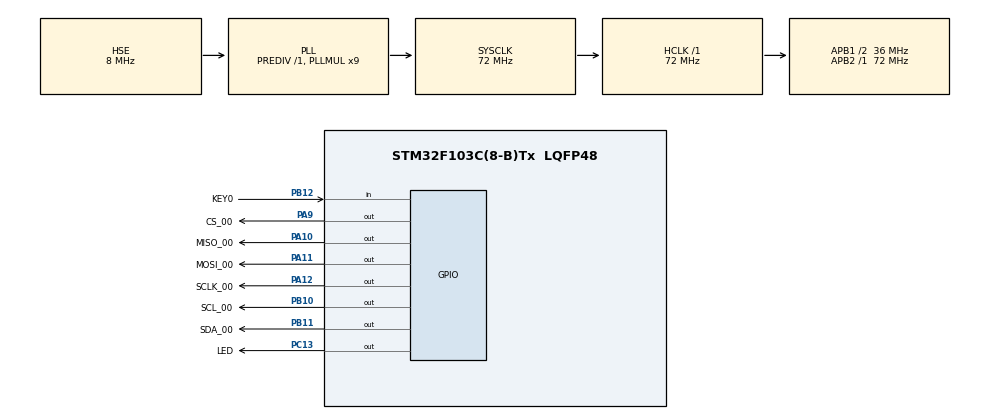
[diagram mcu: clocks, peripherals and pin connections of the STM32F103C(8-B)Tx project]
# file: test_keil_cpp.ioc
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IWDG.Prescaler=IWDG_PRESCALER_64
IWDG.Reload=1000
Mcu.Family=STM32F1
Mcu.Name=STM32F103C(8-B)Tx
Mcu.Package=LQFP48
NVIC.PriorityGroup=NVIC_PRIORITYGROUP_4
PA10.GPIO_Label=MISO_00
PA10.Signal=GPIO_Output
PA11.GPIO_Label=MOSI_00
PA11.Signal=GPIO_Output
PA12.GPIO_Label=SCLK_00
PA12.Signal=GPIO_Output
PA13.Mode=Serial_Wire
PA13.Signal=SYS_JTMS-SWDIO
PA14.Mode=Serial_Wire
PA14.Signal=SYS_JTCK-SWCLK
PA9.GPIO_Label=CS_00
PA9.Signal=GPIO_Output
PB10.GPIO_Label=SCL_00
PB10.Signal=GPIO_Output
PB11.GPIO_Label=SDA_00
PB11.Signal=GPIO_Output
PB12.GPIO_Label=KEY0
PB12.GPIO_PuPd=GPIO_NOPULL
PB12.Signal=GPIO_Input
PC13-TAMPER-RTC.GPIO_Label=LED
PC13-TAMPER-RTC.GPIO_PuPd=GPIO_PULLUP
PC13-TAMPER-RTC.GPIO_Speed=GPIO_SPEED_FREQ_HIGH
PC13-TAMPER-RTC.PinState=GPIO_PIN_SET
PC13-TAMPER-RTC.Signal=GPIO_Output
PC14-OSC32_IN.Mode=LSE-External-Oscillator
PC14-OSC32_IN.Signal=RCC_OSC32_IN
PC15-OSC32_OUT.Mode=LSE-External-Oscillator
PC15-OSC32_OUT.Signal=RCC_OSC32_OUT
PD0-OSC_IN.Mode=HSE-External-Oscillator
PD0-OSC_IN.Signal=RCC_OSC_IN
PD1-OSC_OUT.Mode=HSE-External-Oscillator
PD1-OSC_OUT.Signal=RCC_OSC_OUT
ProjectManager.HeapSize=0x200
ProjectManager.StackSize=0x400
ProjectManager.TargetToolchain=MDK-ARM V5
RCC.AHBFreq_Value=72000000
RCC.APB1CLKDivider=RCC_HCLK_DIV2
RCC.APB1Freq_Value=36000000
RCC.APB1TimFreq_Value=72000000
RCC.APB2Freq_Value=72000000
RCC.APB2TimFreq_Value=72000000
RCC.HCLKFreq_Value=72000000
RCC.PLLMUL=RCC_PLL_MUL9
RCC.PLLSourceVirtual=RCC_PLLSOURCE_HSE
RCC.SYSCLKFreq_VALUE=72000000
RCC.SYSCLKSource=RCC_SYSCLKSOURCE_PLLCLK
RCC.USBFreq_Value=72000000
VP_IWDG_VS_IWDG.Mode=IWDG_Activate
board=custom

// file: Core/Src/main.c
/* USER CODE BEGIN Header */
/**
  ******************************************************************************
  * @file           : main.c
  * @brief          : Main program body
  ******************************************************************************
  * @attention
  *
  * Copyright (c) 2025 STMicroelectronics.
  * All rights reserved.
  *
  * This software is licensed under terms that can be found in the LICENSE file
  * in the root directory of this software component.
  * If no LICENSE file comes with this software, it is provided AS-IS.
  *
  ******************************************************************************
  */
/* USER CODE END Header */
#include "main.h"
#include "iwdg.h"
#include "gpio.h"

/* USER CODE BEGIN Includes */
#include "z_init.h"
#include "z_while.h"
/* USER CODE END Includes */

void SystemClock_Config(void);

int main(void)
{

  /* MCU Configuration--------------------------------------------------------*/

  /* Reset of all peripherals, Initializes the Flash interface and the Systick. */
  HAL_Init();

  /* Configure the system clock */
  SystemClock_Config();

  /* Initialize all configured peripherals */
  MX_GPIO_Init();
  MX_IWDG_Init();
  /* USER CODE BEGIN 2 */
	z_init();
  /* USER CODE END 2 */

  /* Infinite loop */
  while (1)
  {

    /* USER CODE BEGIN 3 */
		z_while();
  }
  /* USER CODE END 3 */
}

void SystemClock_Config(void)
{
  RCC_OscInitTypeDef RCC_OscInitStruct = {0};
  RCC_ClkInitTypeDef RCC_ClkInitStruct = {0};

  /** Initializes the RCC Oscillators according to the specified parameters
  * in the RCC_OscInitTypeDef structure.
  */
  RCC_OscInitStruct.OscillatorType = RCC_OSCILLATORTYPE_LSI|RCC_OSCILLATORTYPE_HSE;
  RCC_OscInitStruct.HSEState = RCC_HSE_ON;
  RCC_OscInitStruct.HSEPredivValue = RCC_HSE_PREDIV_DIV1;
  RCC_OscInitStruct.HSIState = RCC_HSI_ON;
  RCC_OscInitStruct.LSIState = RCC_LSI_ON;
  RCC_OscInitStruct.PLL.PLLState = RCC_PLL_ON;
  RCC_OscInitStruct.PLL.PLLSource = RCC_PLLSOURCE_HSE;
  RCC_OscInitStruct.PLL.PLLMUL = RCC_PLL_MUL9;
  if (HAL_RCC_OscConfig(&RCC_OscInitStruct) != HAL_OK)
  {
    Error_Handler();
  }

  /** Initializes the CPU, AHB and APB buses clocks
  */
  RCC_ClkInitStruct.ClockType = RCC_CLOCKTYPE_HCLK|RCC_CLOCKTYPE_SYSCLK
                              |RCC_CLOCKTYPE_PCLK1|RCC_CLOCKTYPE_PCLK2;
  RCC_ClkInitStruct.SYSCLKSource = RCC_SYSCLKSOURCE_PLLCLK;
  RCC_ClkInitStruct.AHBCLKDivider = RCC_SYSCLK_DIV1;
  RCC_ClkInitStruct.APB1CLKDivider = RCC_HCLK_DIV2;
  RCC_ClkInitStruct.APB2CLKDivider = RCC_HCLK_DIV1;

  if (HAL_RCC_ClockConfig(&RCC_ClkInitStruct, FLASH_LATENCY_2) != HAL_OK)
  {
    Error_Handler();
  }
}

void Error_Handler(void)
{
  __disable_irq();
  while (1)
  {
  }
}
